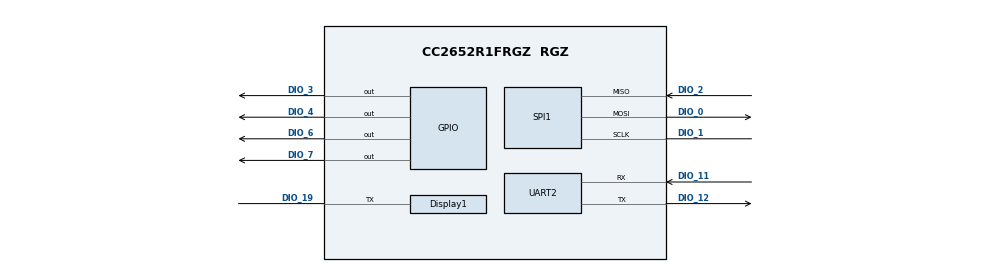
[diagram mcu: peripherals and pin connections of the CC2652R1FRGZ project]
/**
 * @cliArgs --device "CC2652R1FRGZ" --package "RGZ" --part "Default" --product "simplelink_cc13x2_26x2_sdk@4.30.00.54"
 * @versions {"data":"2020090214","timestamp":"2020090214","tool":"1.6.0+1543","templates":"2020090214"}
 */

/**
 * Import the modules used in this configuration.
 */
const ble         = scripting.addModule("/ti/ble5stack/ble");
const CCFG        = scripting.addModule("/ti/devices/CCFG");
const rfdesign    = scripting.addModule("/ti/devices/radioconfig/rfdesign");
const Display     = scripting.addModule("/ti/display/Display");
const Display1    = Display.addInstance();
const AESCCM      = scripting.addModule("/ti/drivers/AESCCM");
const AESCCM1     = AESCCM.addInstance();
const AESCTRDRBG  = scripting.addModule("/ti/drivers/AESCTRDRBG");
const AESCTRDRBG1 = AESCTRDRBG.addInstance();
const AESECB      = scripting.addModule("/ti/drivers/AESECB");
const AESECB1     = AESECB.addInstance();
const Board       = scripting.addModule("/ti/drivers/Board");
const ECDH        = scripting.addModule("/ti/drivers/ECDH");
const ECDH1       = ECDH.addInstance();
const GPIO        = scripting.addModule("/ti/drivers/GPIO");
const GPIO1       = GPIO.addInstance();
const GPIO2       = GPIO.addInstance();
const GPIO3       = GPIO.addInstance();
const GPIO4       = GPIO.addInstance();
const NVS         = scripting.addModule("/ti/drivers/NVS");
const NVS1        = NVS.addInstance();
const Power       = scripting.addModule("/ti/drivers/Power");
const RF          = scripting.addModule("/ti/drivers/RF");
const RTOS        = scripting.addModule("/ti/drivers/RTOS");
const SPI         = scripting.addModule("/ti/drivers/SPI", {}, false);
const SPI1        = SPI.addInstance();
const TRNG        = scripting.addModule("/ti/drivers/TRNG");
const TRNG1       = TRNG.addInstance();
const UART        = scripting.addModule("/ti/drivers/UART", {}, false);
const UART2       = UART.addInstance();

/**
 * Write custom configuration values to the imported modules.
 */
ble.lockProject                                     = true;
ble.deviceName                                      = "Project Zero";
ble.addressMode                                     = "ADDRMODE_PUBLIC";
ble.disableDisplayModule                            = true;
ble.uartLog                                         = true;
ble.numOfAdvSets                                    = 1;
ble.numOfDefAdvSets                                 = 1;
ble.biasConfiguration                               = "RF_FE_EXT_BIAS";
ble.frontEndMode                                    = "RF_FE_SINGLE_ENDED_RFP";
ble.maxConnNum                                      = 1;
ble.maxPDUSize                                      = 251;
ble.defaultTxPower                                  = "HCI_EXT_TX_POWER_5_DBM";
ble.maxPDUNum                                       = 80;
ble.radioConfig.codeExportConfig.$name              = "ti_devices_radioconfig_code_export_param0";
ble.connUpdateParamsPeripheral.$name                = "ti_ble5stack_general_ble_conn_update_params0";
ble.connUpdateParamsPeripheral.reqConnTo            = 2000;
ble.connUpdateParamsPeripheral.reqMaxConnInt        = 45;
ble.connUpdateParamsPeripheral.reqMinConnInt        = 15;
ble.advSet1.$name                                   = "ti_ble5stack_broadcaster_advertisement_set0";
ble.advSet1.advParam1.$name                         = "ti_ble5stack_broadcaster_advertisement_params0";
ble.advSet1.advData1.$name                          = "ti_ble5stack_broadcaster_advertisement_data0";
ble.advSet1.advData1.GAP_ADTYPE_FLAGS               = true;
ble.advSet1.advData1.advertisingFlags               = ["GAP_ADTYPE_FLAGS_BREDR_NOT_SUPPORTED","GAP_ADTYPE_FLAGS_GENERAL"];
ble.advSet1.advData1.GAP_ADTYPE_LOCAL_NAME_COMPLETE = true;
ble.advSet1.advData1.completeLocalName              = "Project Zero";
ble.advSet1.scanRes1.$name                          = "ti_ble5stack_broadcaster_advertisement_data1";
ble.advSet1.scanRes1.GAP_ADTYPE_128BIT_MORE         = true;
ble.advSet1.scanRes1.numOfUUIDs128More              = 1;
ble.advSet1.scanRes1.UUID0128More                   = system.utils.bigInt("B000405104101100F0",16);

CCFG.enableCodeGeneration = false;
CCFG.srcClkHF             = "External 48Mhz TCXO";
CCFG.xoscCapArray         = true;
CCFG.ccfgTemplate.$name   = "ti_devices_CCFGTemplateInit0";

rfdesign.fe24g = "XS_RFP";

Display1.$name                          = "CONFIG_Display_0";
Display1.enableANSI                     = true;
Display1.uartBufferSize                 = 128;
Display1.uart.$name                     = "CONFIG_DISPLAY_UART";
Display1.uart.ringBufferSize            = 250;
Display1.uart.uart.$assign              = "UART1";
Display1.uart.uart.txPin.$assign        = "DIO_19";
Display1.uart.txPinInstance.outputState = "High";
Display1.uart.txPinInstance.$name       = "CONFIG_PIN_UART_TX";
Display1.uart.rxPinInstance.$name       = "CONFIG_PIN_UART_RX";

AESCCM1.$name = "CONFIG_AESCCM0";

AESCTRDRBG1.$name              = "CONFIG_AESCTRDRBG_0";
AESCTRDRBG1.aesctrObject.$name = "CONFIG_AESCTR_0";

AESECB1.$name = "CONFIG_AESECB0";

ECDH1.$name = "CONFIG_ECDH0";

GPIO1.pull              = "Pull Up";
GPIO1.$name             = "CONFIG_GPIO_BTN1";
GPIO1.mode              = "Output";
GPIO1.gpioPin.$assign   = "DIO_3";
GPIO1.pinInstance.$name = "CONFIG_PIN_BTN1";

GPIO2.pull              = "Pull Up";
GPIO2.interruptTrigger  = "Falling Edge";
GPIO2.mode              = "Dynamic";
GPIO2.$name             = "CONFIG_GPIO_BTN2";
GPIO2.gpioPin.$assign   = "DIO_4";
GPIO2.pinInstance.$name = "CONFIG_PIN_BTN2";

GPIO3.mode              = "Dynamic";
GPIO3.$name             = "CONFIG_GPIO_RLED";
GPIO3.gpioPin.$assign   = "DIO_6";
GPIO3.pinInstance.$name = "CONFIG_PIN_RLED";

GPIO4.mode              = "Dynamic";
GPIO4.$name             = "CONFIG_GPIO_GLED";
GPIO4.gpioPin.$assign   = "DIO_7";
GPIO4.pinInstance.$name = "CONFIG_PIN_GLED";

NVS1.$name                    = "CONFIG_NVSINTERNAL";
NVS1.internalFlash.$name      = "ti_drivers_nvs_NVSCC26XX0";
NVS1.internalFlash.regionBase = 0x48000;
NVS1.internalFlash.regionSize = 0x4000;

SPI1.$name                    = "CONFIG_SPI_1";
SPI1.defaultTxBufferValue     = "0x55";
SPI1.minDmaTransferSize       = 27;
SPI1.spi.sclkPin.$assign      = "DIO_1";
SPI1.spi.misoPin.$assign      = "DIO_2";
SPI1.spi.mosiPin.$assign      = "DIO_0";
SPI1.spi.dmaRxChannel.$assign = "DMA_CH3";
SPI1.spi.dmaTxChannel.$assign = "DMA_CH4";
SPI1.sclkPinInstance.$name    = "CONFIG_PIN_6";
SPI1.misoPinInstance.$name    = "CONFIG_PIN_7";
SPI1.mosiPinInstance.$name    = "CONFIG_PIN_8";

TRNG1.$name = "CONFIG_TRNG_0";

UART2.$name               = "CONFIG_UART_0";
UART2.uart.$assign        = "UART0";
UART2.uart.txPin.$assign  = "DIO_12";
UART2.uart.rxPin.$assign  = "DIO_11";
UART2.txPinInstance.$name = "CONFIG_PIN_4";
UART2.rxPinInstance.$name = "CONFIG_PIN_5";

/**
 * Pinmux solution for unlocked pins/peripherals. This ensures that minor changes to the automatic solver in a future
 * version of the tool will not impact the pinmux you originally saw.  These lines can be completely deleted in order to
 * re-solve from scratch.
 */
Display1.uart.uart.rxPin.$suggestSolution = "DIO_10";
SPI1.spi.$suggestSolution                 = "SSI0";
